# netx90_app register map
File version: 1.0
CPU: CM4 r0p1, little endian, MPU, FPU, 4 interrupt priority bits, 78 interrupts
Registers are 32-bit, read-write, reset 0x0 unless marked. A register's access mark holds for its fields unless they carry their own. Offsets are from the block's base; [hi:lo] are bit positions; {n}, {i} and the like mark numbered series; <NAME> marks a mode.

## sqi0_app
Base 0xFF801180
Same registers: sqi1_app 0xFF8011C0
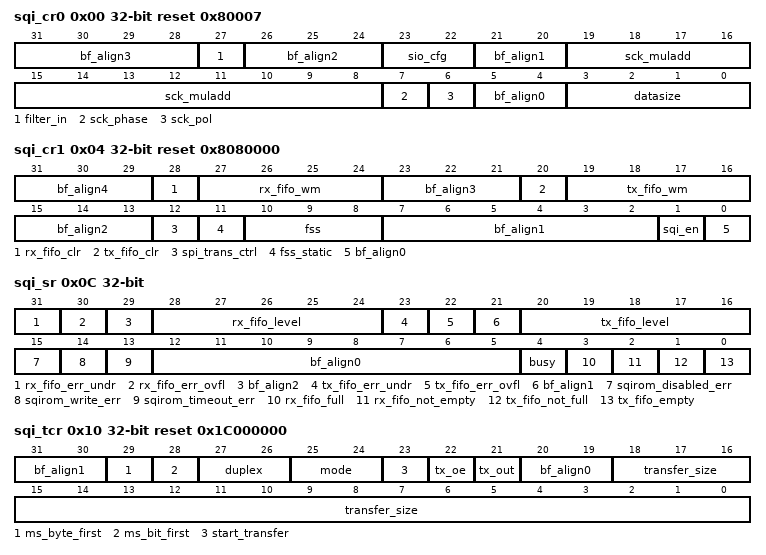
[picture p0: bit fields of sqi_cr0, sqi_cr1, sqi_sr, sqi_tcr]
0x00 sqi_cr0 reset 0x80007 (reset mask 0x8CFFFCF) — SQI control register 0 This register is compatible with the netX50 and netX10 SPI module, but some additional settings are possible. The SQI module provides master function only. Slave settings are omitted. The SQI module does not support the compatible mode for netX100.
  [31:28] bf_align3 — bitField alignment value for aeabi compatibility
  [27] filter_in — Input filtering Receive data is sampled every 10 ns (100 MHz system clock). If this bit is set, the stored receive value will be the result of a majority decision of the three sampling points around an sck clock edge (if two or more '1's have been sampled, a '1' will be stored. If this bit is not set, a '0' will be stored). Input filtering should be used for sck_muladd<=0x200 (i.e. below 12.5 MHz). For higher frequencies, stable signal phases are too short for filtering.
  [26:24] bf_align2 — bitField alignment value for aeabi compatibility
  [23:22] sio_cfg — SQI IO configuration Default: All additional SQI-IOs (SIO2+3) are in PIO input mode. Coding 00: only SIO2+3 are controllable as PIOs (2-bit SPI or standard Motorola SPI) 01: all SQI IOs are used for transfers (4-bit SPI/SQI) 10: reserved 11: all SQI IOs are controllable as PIOs
  [21:20] bf_align1 — bitField alignment value for aeabi compatibility
  [19:8] sck_muladd — Serial clock rate multiply add value for sck generation sck-frequency: f_sck = (sck_muladd * 100)/4096 [MHz]. Programmed value of sck_muladd must be <= 0x800. Default value 0x800 equals 50 MHz clock rate. Note: If sck_muladd is set to zero, transfer will freeze. Note: SQIROM (XiP) serial clock rate must be programmed in register 'sqi_sqirom_cfg'.
  [7] sck_phase — Serial clock phase 1: Sample data at second clock edge, data is generated half a clock phase before sampling 0: Sample data at first clock edge, data is generated half a clock phase before sampling Note: sck_phase value equals bit 0 of SPI mode value (mode = (sck_pol, sck_phase)).
  [6] sck_pol — Serial clock polarity 0: idle: clock is low, first edge is rising 1: idle: clock is high, first edge is falling Note: sck_pol value equals bit 1 of SPI mode value (mode = (sck_pol, sck_phase)).
  [5:4] bf_align0 — bitField alignment value for aeabi compatibility
  [3:0] datasize — Data size select for standard Motorola SPI mode This bit field is unused in 2-bit and 4-bit SPI modes (i.e. data size fixed to 8 bit). The actual transfer size is 'datasize' + 1 bit. { | 0000...0010: reserved 0011: 4 bit 0100: 5 bit ... 0111: 8 bit ... 1111: 16 bit }
0x04 sqi_cr1 reset 0x8080000 (reset mask 0x1F1F1F02) — SQI control register 1 This register is compatible with the netX50 and netX10 SPI module, but some additional settings are possible. The SQI module provides master function only. Slave settings are omitted.
  [31:29] bf_align4 — bitField alignment value for aeabi compatibility
  [28] rx_fifo_clr — Receive FIFO clear Writing '1' to this bit will clear the receive FIFO. The hardware will automatically reset this bit. This bit is always '0' when read.
  [27:24] rx_fifo_wm — Receive FIFO watermark for IRQ generation If the receive FIFO watermark IRQ is enabled (bit 'RXIM' is set in register 'sqi_irq_mask'), transfers will stop when the receive FIFO runs full. Transfers will continue after the receive data is read from the receive FIFO to avoid an overflow of the receive FIFO. If the receive FIFO watermark IRQ is disabled (bit 'RXIM' is not set in register 'sqi_irq_mask'), transfers will not stop when the receive FIFO runs full. This may cause an overflow of the receive FIFO. This is compatible with netX50 behavior and allows writing data in full-duplex mode without reading the receive FIFO.
  [23:21] bf_align3 — bitField alignment value for aeabi compatibility
  [20] tx_fifo_clr — Transmit FIFO clear Writing '1' to this bit will clear the transmit FIFO. The hardware will automatically reset this bit. This bit is always '0' when read.
  [19:16] tx_fifo_wm — Transmit FIFO watermark for IRQ generation
  [15:13] bf_align2 — bitField alignment value for aeabi compatibility
  [12] spi_trans_ctrl — Transfer control for standard Motorola SPI (default: disabled) This bit is used only for standard Motorola SPI (bits 'mode' of register 'sqi_tcr') in full-duplex and half-duplex mode. If this bit is set, SPI transfers will be controlled by 'start_transfer' and 'transfer_size' of register 'sqi_tcr'. If this bit is not set (default), SPI transfers start immediately after transfer data has been written to TX FIFO (this is compatible with the SPI module). Settings of 'start_transfer' and 'transfer_size' of register 'sqi_tcr' then remain unaffected and will be ignored. If this bit is set and SPI is used in receive mode (full-duplex or half-duplex receive mode set by bit field 'duplex' in register 'sqi_tcr'), transfers will stop when the receive FIFO runs full. Transfers will continue after the receive data is read from the receive FIFO to avoid an overflow of the receive FIFO.
  [11] fss_static — SQI static chip select 0: Chip select will be generated automatically at data frame begin/end according to fss and datasize. 1: Chip select will be set statically according to 'fss' bits (see below). If fss is set to static mode, fss must be toggled manually after each data frame in Motorola SPI mode when sck_phase is 0 for compatibility with the specification! Note: This bit is used only in standard Motorola SPI mode. For SQI modes, chip select is never generated automatically.
  [10:8] fss — Frame slave select Up to 3 devices can be assigned directly. Up to 8 devices can be assigned if an external de-multiplexer is used. This signal is active low, i.e. the bits will be inverted before they are output to the SQI pins.
  [7:2] bf_align1 — bitField alignment value for aeabi compatibility
  [1] sqi_en — SQI enable 0: Interface disabled 1: Interface enabled Note: If you select the SQIROM/XiP function by bit 'enable' of register 'sqi_sqirom_cfg' (see description of register 'sqi_sqirom_cfg'), the standard SQI/SPI function will not be available.
  [0] bf_align0 — bitField alignment value for aeabi compatibility
0x08 sqi_dr — SQI data register (DR) Read access: Received data word is delivered from receive FIFO. Write access: Data word to be sent is written to send FIFO. Receive and transmit FIFO both have a depth of 16 words (standard SPI mode). The SQI mode combines both FIFOs, i.e. 64 bytes are available.
  [31:0] data — Transmit data The data must be right-aligned during writing. In Standard SPI mode only bits according to sqi_cr0.datasize are transferred. In SQI mode data must be written in full DWords (i.e. the software has to collect four bytes prior to writing). Unused bytes will not be transferred and may be padded at will (number of transferred bytes depends on sqi_tcr.transfer_size). Receive data will always be right-aligned; unused bits will be '0'.
0x0C sqi_sr ro (reset mask 0xDFDFE01F) — Read-only SQI status register Shows the current status of the SQI interface.
  [31] rx_fifo_err_undr — Receive FIFO underrun error has occurred, unexpected data has been read. To clear this status flag, clear RX FIFO (register 'sqi_cr1').
  [30] rx_fifo_err_ovfl — Receive FIFO overflow error occurred, data is lost. To clear this status flag, clear RX FIFO (register 'sqi_cr1').
  [29] bf_align2 — bitField alignment value for aeabi compatibility
  [28:24] rx_fifo_level — Receive FIFO level (number of received words to be read from the FIFO).
  [23] tx_fifo_err_undr — Transmit FIFO underrun error has occurred, unexpected data has been sent. To clear this status flag, clear TX FIFO (register 'sqi_cr1').
  [22] tx_fifo_err_ovfl — Transmit FIFO overflow error occurred, data is lost. To clear this status flag, clear TX FIFO (register 'sqi_cr1').
  [21] bf_align1 — bitField alignment value for aeabi compatibility
  [20:16] tx_fifo_level — Transmit FIFO level (number of words to be transmitted are left in the FIFO).
  [15] sqirom_disabled_err — Access to the disabled SQIROM area has occurred. To enable the SQIROM function, set bit 'enable' in register 'sqi_sqirom_cfg'. This bit can be used to determine why the IRQ 'sqirom_error' has occurred. Clearing this status flag is possible only by writing a '1' here.
  [14] sqirom_write_err — Write access to the read-only SQIROM area has occurred. This bit can be used to determine why the IRQ 'sqirom_error' has occurred. Clearing this status flag is possible only by writing a '1' here.
  [13] sqirom_timeout_err — Timeout during a read of the SQIROM area has occurred. A timeout results from a fix level of the netX serial clock IO. Check IO multiplexing configuration and make sure that the serial clock output is not externally clamped. This bit can be used to determine why the IRQ 'sqirom_error' has occurred. Clearing this status flag is possible only by writing a '1' here. The SQIROM function must be disabled and enabled again to reset module-internal state machines after this bit has been set (register 'sqirom_cfg', therefore reset and set again the 'enable' bit).
  [12:5] bf_align0 — bitField alignment value for aeabi compatibility
  [4] busy — Device is busy 1 if data is currently transmitted/received or the transmit FIFO is not empty.
  [3] rx_fifo_full — Receive FIFO is full (1 if full).
  [2] rx_fifo_not_empty — Receive FIFO is not empty (0 if empty).
  [1] tx_fifo_not_full — Transmit FIFO is not full (0 if full).
  [0] tx_fifo_empty — Transmit FIFO is empty (1 if empty).
0x10 sqi_tcr reset 0x1C000000 (reset mask 0x3FE7FFFF) — SQI transfer control This register must not be changed during a transfer (bit 'busy' of register 'sqi_sr' is '1') to avoid corrupted transfers causing damage to the hardware. Module address offset 0x10 is reserved in the netX10/50 SPI module. Thus, no compatibility problems will result from using this address for extended transfer control features.
  [31:30] bf_align1 — bitField alignment value for aeabi compatibility
  [29] ms_byte_first — Most significant byte first 2- and 4-bit mode: Writing '1' to this bit will use most significant byte first in DWords (big endian). Default is little endian In standard Motorola SPI mode this bit is ignored.
  [28] ms_bit_first — Most significant bit first 2- and 4-bit mode: Writing '1' to this bit will transfer most significant bit first (default). In standard Motorola SPI mode this bit is ignored.
  [27:26] duplex — Transfer type selection Default is '11' for standard SPI compatibility. 00: dummy Generates 'transfer_size' + 1 serial clock periods. No change of RX and TX FIFOs. Data lines (standard Motorola SPI mode: SPI_MOSI) are controlled by 'tx_oe' and 'tx_out'. 01: half-duplex receive Receives 'transfer_size' + 1 words. In 2-bit and 4-bit mode, TX-FIFO will be cleared and is not available during receive. In standard SPI mode, SPI_MOSI is controlled by 'tx_oe' and 'tx_out'. You need not fill the TX-FIFO with dummy TX-data to receive RX-data. TX FIFOs are not changed and always available. 10: half-duplex transmit Transmits 'transfer_size' + 1 words. In 2-bit and 4-bit mode, RX-FIFO will be cleared and is not available during transmit. In standard SPI mode, SPI_MISO input is ignored. RX-FIFO is available and remains unchanged. 11: full-duplex Standard Motorola SPI mode only, reserved in 2-bit and 4-bit modes. The full-duplex standard Motorola SPI mode always transmits and receives data. Transmit data is taken from TX-FIFO, receive data is stored in RX-FIFO. Note: If '11' is set in 2-bit or 4-bit mode, this is treated as 'receive' (like '01' setting). Note: In case of a FIFO error (overflow, underrun) before changing to '01' or '10', the FIFO error status bits in register 'sqi_sr' will not be cleared by half-duplex modes FIFO clearing.
  [25:24] mode — SPI/SQI mode selection 00: Standard Motorola SPI mode. 01: 2-bit SPI mode 10: 4-bit SPI mode 11: reserved
  [23] start_transfer — Transfer start signal Writing a '1' starts the transfer of transfer_size bytes or dummy cycles. The hardware will automatically reset this bit. This bit is always '0' when read. This bit is writable only after a transfer sequence is finished or if it has been terminated by a FIFO clear. Note: A transfer sequence is finished completely when 'busy' of register 'sqi_sr' is not set. Note: In standard Motorola SPI mode, this function can be controlled by bit 'spi_trans_ctrl' of register 'sqi_cr1' (for SPI module compatibility).
  [22] tx_oe — Output driver enable in dummy or standard SPI receive-only mode Writing a '1' enables the output drivers of the data pins in the dummy mode.
  [21] tx_out — Output level in dummy or standard SPI receive-only mode This bit selects the output level when the output driver is enabled in the dummy mode.
  [20:19] bf_align0 — bitField alignment value for aeabi compatibility
  [18:0] transfer_size — Number of bytes within the current SQI transaction Program (number of bytes - 1) or (number of dummy clock cycles - 1). Example: { | 0x00000: one byte/dummy cycle ... 0x7ffff: 512k bytes/dummy cycles } This bit field counts down during transfers with each transferred word/byte or dummy cycle. This bit field is writable only after a transfer sequence is finished or if it has been terminated by a FIFO clear. Hence, this bit is writable, but it can also be changed by hardware. A running transfer sequence can be terminated by clearing the FIFO (register 'sqi_cr1'). This may become necessary for terminating a read sequence. Example: A half-duplex write transfer of 128 kbytes has been programmed, but there is not enough write data. To terminate this write sequence, clear the TX FIFO. If an external transfer is running while the FIFO is being cleared, this transfer will be continued and finished with the last bit to be transferred. Note: A transfer sequence is finished completely when 'busy' of register 'sqi_sr' is not set.
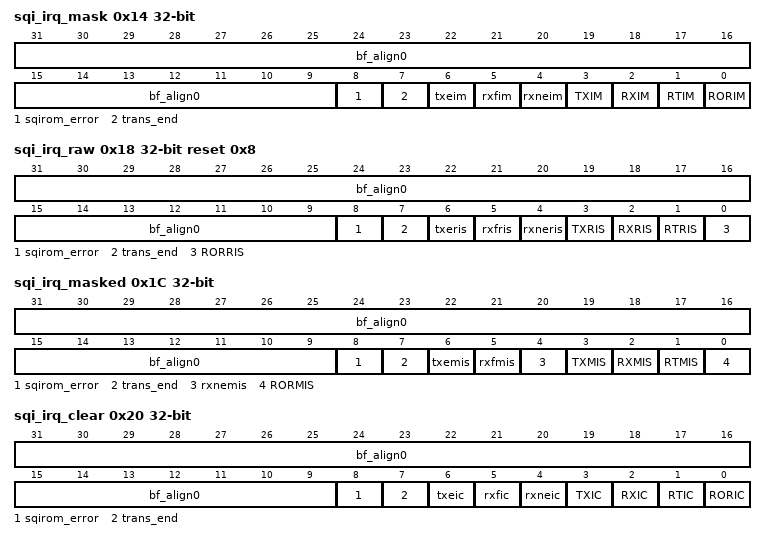
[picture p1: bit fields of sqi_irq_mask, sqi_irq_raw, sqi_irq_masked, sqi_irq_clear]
0x14 sqi_irq_mask (reset mask 0x1FF) — SQI interrupt mask register: IRQ mask is an AND-mask: Only raw interrupts with mask bit set can generate a module IRQ to CPU. For detailed IRQ behavior and function, see register 'sqi_irq_raw'. The functionality of this register is similar to that of the corresponding SPI register spi_imsc. In contrast to this register, setting bits in spi_imsc also clears the corresponding raw interrupts.
  [31:9] bf_align0 — bitField alignment value for aeabi compatibility
  [8] sqirom_error — SQIROM error interrupt mask
  [7] trans_end — Transfer end interrupt mask
  [6] txeim — Transmit FIFO empty interrupt mask (for compatibility with netx100/500)
  [5] rxfim — Receive FIFO full interrupt mask (for compatibility with netx100/500)
  [4] rxneim — Receive FIFO not empty interrupt mask (for compatibility with netx100/500)
  [3] TXIM — Transmit FIFO interrupt mask
  [2] RXIM — Receive FIFO interrupt mask
  [1] RTIM — Receive timeout interrupt mask
  [0] RORIM — Receive FIFO overrun interrupt mask
0x18 sqi_irq_raw reset 0x8 (reset mask 0x1FF) — SQI interrupt state before masking register (raw interrupt). Writing a '1' to a bit clears this interrupt. IRQ flags can also be cleared by using 'sqi_irq_clear' for SPI module compatibility.
  [31:9] bf_align0 — bitField alignment value for aeabi compatibility
  [8] sqirom_error — Unmasked SQIROM error interrupt state 1: SQIROM access error detected. This IRQ will be set if an error occurs during an SQIROM access. For detailed information on the error, see SQIROM error bits in register 'sqi_sr'. For error handling, clear this IRQ bit and the bits of register 'sqi_sr'. 0: no SQIROM error detected.
  [7] trans_end — Unmasked transfer end interrupt state (related to bit 'busy' of register 'sqi_sr') 1: transfer finished. Bit 'busy' of register 'sqi_sr' has become inactive. 0: transfer not finished. Bit 'busy' of register 'sqi_sr' is active.
  [6] txeris — Unmasked transmit FIFO empty interrupt state (for compatibility with netx100/500) 1: transmit FIFO is empty 0: transmit FIFO is not empty
  [5] rxfris — Unmasked receive FIFO full interrupt state (for compatibility with netx100/500) 1: receive FIFO is full 0: receive FIFO is not full
  [4] rxneris — Unmasked receive FIFO not empty interrupt state (for compatibility with netx100/500) 1: receive FIFO is not empty 0: receive FIFO is empty
  [3] TXRIS — Unmasked transmit FIFO interrupt state 1: transmit FIFO level is below sqi_cr1.tx_fifo_wm 0: transmit FIFO is equal or higher than sqi_cr1.tx_fifo_wm
  [2] RXRIS — Unmasked receive FIFO interrupt state 1: receive FIFO is higher than sqi_cr1.rx_fifo_wm 0: receive FIFO is equal or below sqi_cr1.rx_fifo_wm Note: Before programming this IRQ, see description of bits 'spi_trans_ctrl' and 'rx_fifo_wm' of register 'sqi_cr1' for receive FIFO behavior.
  [1] RTRIS — Unmasked receive timeout interrupt state Timeout period is 32 serial clock periods (depending on adr_sqi_cr0.sck_muladd). 1: receive FIFO is not empty and has not been read out during the timeout period 0: receive FIFO is empty or read during the last timeout period
  [0] RORRIS — Unmasked receive FIFO overrun interrupt state 1: receive FIFO overrun error occurred 0: no receive FIFO overrun error occurred
0x1C sqi_irq_masked ro (reset mask 0x1FF) — SQI masked interrupt status register For detailed IRQ behavior and function, see register 'sqi_irq_raw'.
  [31:9] bf_align0 — bitField alignment value for aeabi compatibility
  [8] sqirom_error — Masked SQIROM error interrupt state
  [7] trans_end — Masked transfer end interrupt state
  [6] txemis — Masked transmit FIFO empty interrupt state (for compatibility with netx100/500)
  [5] rxfmis — Masked receive FIFO full interrupt state (for compatibility with netx100/500)
  [4] rxnemis — Masked receive FIFO not empty interrupt state (for compatibility with netx100/500)
  [3] TXMIS — Masked transmit FIFO interrupt state
  [2] RXMIS — Masked receive FIFO interrupt state
  [1] RTMIS — Masked receive timeout interrupt state
  [0] RORMIS — Masked receive FIFO overrun interrupt state
0x20 sqi_irq_clear (reset mask 0x1FF) — SQI interrupt clear register (for compatibility with netX10/50 SPI module). This register is always '0' on read. IRQ flags can also be cleared by writing register 'sqi_irq_raw'.
  [31:9] bf_align0 — bitField alignment value for aeabi compatibility
  [8] sqirom_error — Clear SQIROM error interrupt
  [7] trans_end — Clear transfer end interrupt
  [6] txeic — Clear transmit FIFO empty interrupt (for compatibility with netx100/500)
  [5] rxfic — Clear receive FIFO full interrupt (for compatibility with netx100/500)
  [4] rxneic — Clear receive FIFO not empty interrupt (for compatibility with netx100/500)
  [3] TXIC — Clear transmit FIFO interrupt
  [2] RXIC — Clear receive FIFO interrupt
  [1] RTIC — Clear receive timeout interrupt
  [0] RORIC — Clear receive FIFO overrun interrupt
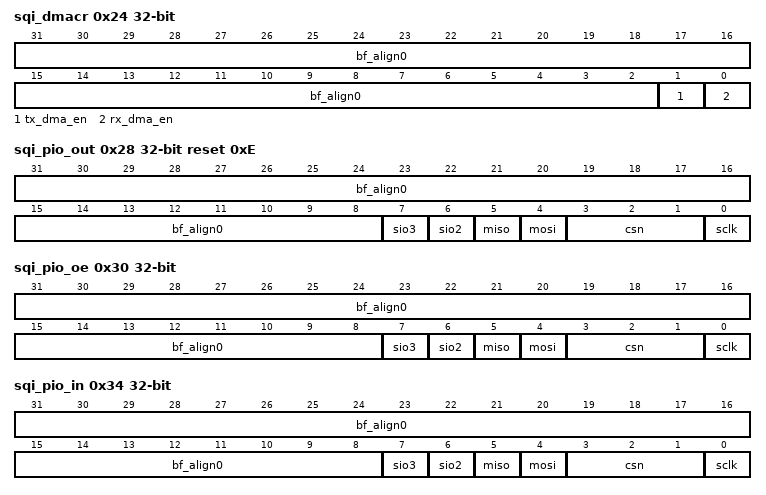
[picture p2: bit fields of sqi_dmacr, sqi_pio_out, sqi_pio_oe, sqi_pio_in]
0x24 sqi_dmacr (reset mask 0x3) — SQI DMA control register This module generates normal transfer requests only (i.e. no last requests will be issued). In consequence, you can use DMAC-controlled transfers only (no peripheral-controlled mode).
  [31:2] bf_align0 — bitField alignment value for aeabi compatibility
  [1] tx_dma_en — Enable DMA for SQI-transmit data A request will be generated if TX-FIFO is not full and sqi_cr1.sqi_en (module enable) is set. If at least 4 words are writable to the TX-FIFO, there will be a burst request to the DMAC. Set dmac_chctrl.DBSize = 1 (i.e. burst size: 4) in the DMAC module. If this bit is reset or the module is disabled, DMA request will also be reset.
  [0] rx_dma_en — Enable DMA for SQI-receive data A request will be generated if RX-FIFO is not empty and sqi_cr1.sqi_en (module enable) is set. If the RX-FIFO contains at least 4 words, there will be a burst request to the DMAC. Set dmac_chctrl.SBSize = 1 (i.e. burst size: 4) in the DMAC module. If this bit is reset or the module is disabled, DMA request will also be reset.
0x28 sqi_pio_out reset 0xE (reset mask 0xFF) — SQI PIO output level control register Bits 'sio_cfg' of register 'sqi_cr0' control the IO PIO mode. Bit 'sqi_en' of register 'sqi_cr0' has to be set to drive the SQI IOs in the PIO mode. PIO input signal states are never filtered (bit 'filter_in' of register 'sqi_cr0').
  [31:8] bf_align0 — bitField alignment value for aeabi compatibility
  [7] sio3 — SIO3 output state
  [6] sio2 — SIO2 output state
  [5] miso — MISO/SIO1 output state
  [4] mosi — MOSI/SIO0 output state
  [3:1] csn — Chip select/FSS output state {CS2, CS1, CS0}
  [0] sclk — Serial SPI clock output state
0x30 sqi_pio_oe (reset mask 0xFF) — SQI PIO output enable control register Bits 'sio_cfg' of register 'sqi_cr0' control the IO PIO mode. Bit 'sqi_en' of register 'sqi_cr0' has to be set to drive the SQI IOs in the PIO mode.
  [31:8] bf_align0 — bitField alignment value for aeabi compatibility
  [7] sio3 — SIO3 output enable
  [6] sio2 — SIO2 output enable
  [5] miso — MISO/SIO1 output enable
  [4] mosi — MOSI/SIO0 output enable
  [3:1] csn — Chip select/FSS output enable {CS2, CS1, CS0}
  [0] sclk — Serial SPI clock output enable
0x34 sqi_pio_in ro (reset mask 0xFF) — SQI PIO input status register Bits 'sio_cfg' of register 'sqi_cr0' control the IO PIO mode.
  [31:8] bf_align0 — bitField alignment value for aeabi compatibility
  [7] sio3 — SIO3 input state
  [6] sio2 — SIO2 input state
  [5] miso — MISO/SIO1 input state
  [4] mosi — MOSI/SIO0 input state
  [3:1] csn — Chip select/FSS input state {CS2, CS1, CS0}
  [0] sclk — Serial SPI clock input state
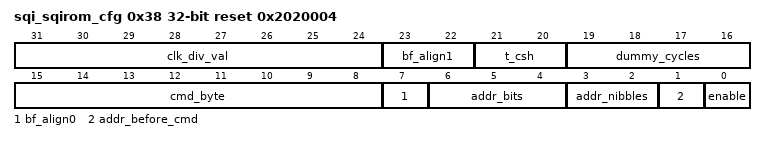
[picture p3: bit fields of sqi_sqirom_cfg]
0x38 sqi_sqirom_cfg reset 0x2020004 (reset mask 0xFF3FFF7F) — SQIROM mode configuration This mode supports the 'eXecute in Place' (XiP) feature of SQI flash chips. This register serves to configure the position of command byte and address nibbles as well as the number of address nibbles and dummy cycles. To support a wide range of frequencies for the serial clock output, you can also change the clock divider. Notes: 1. Before enabling this mode, make sure that the SQI flash chip is in 4-bit command mode, otherwise the module is not able to fetch data from the flash. 2. When enabled, the SQI module is completely blocked, i.e. other SQI or SPI transactions are not possible. 3. The chip select signal of the flash must be connected to sqi_cs0. 4. SQIROM transfers can be generated in SPI mode 0 or 3, which can be selected in register 'sqi_cr0'. DO NOT select mode 1 and 2 for SQIROM usage.
  [31:24] clk_div_val — clk400 will be divided by (clk_div_val+3) for sqirom_clk generation. Default setting '2' is 80 MHz. Maximum serial clock rate (programming '0') is 133 MHz. Serial clock period (t_sck) will be (clk_div_val+3) * 2.5 ns. Clock high and low phase will be generated symmetrically.
  [23:22] bf_align1 — bitField alignment value for aeabi compatibility
  [21:20] t_csh — Min. SQI chip select high (idle) time: (t_csh+1) * t_sck (according to clk_div_val). Programmable values are 0 to 3. Change this parameter if the SQI device used requires min. chip select high times exceeding 1 serial clock period. The data sheet of the SQI device used provides the required timing. Note: Serial clock will not toggle if the device is not selected. Hence, only chip select active timing has to be considered.
  [19:16] dummy_cycles — Selects the number of dummy cycles before data will be sampled from the SQI chip. { | 0000: 0 cycles 0001: 1 cycle 0010: 2 cycles (default) ... 1111: 15 cycles }
  [15:8] cmd_byte — This byte is transferred to the SQI chip as the command sequence. Bit 'addr_before_cmd' controls the address command order.
  [7] bf_align0 — bitField alignment value for aeabi compatibility
  [6:4] addr_bits — The number of address bits of the access address considered to generate the address for the SQI chip. This setting depends on the size of the SQI chip. { | 000: 20 bits (1-MByte/8-MBit device) (default) 001: 21 bits (2-MByte/16-MBit device) 010: 22 bits (4-MByte/32-MBit device) 011: 23 bits (8-MByte/64-MBit device) 100: 24 bits (16-MByte/128-MBit device) 101: 25 bits (32-MByte/256-MBit device) 110: 26 bits (64-MByte/512-MBit device) 111: reserved }
  [3:2] addr_nibbles — The number of nibbles to be transferred as the address to the SQI chip. This setting depends on the command format of the SQI chip. Bit 'addr_before_cmd' controls the address command order. The most significant address bits will be transmitted in the first address nibble. The least significant address bits will be transmitted in the last address nibble. 00: 5 nibbles 01: 6 nibbles (default) 10: 7 nibbles 11: 8 nibbles
  [1] addr_before_cmd — Address before command When set to '1', the address nibbles will be transferred before the command byte. Otherwise, the command will be transferred first (default).
  [0] enable — Enables the SQIROM mode of the SQI module. The SQI chip needs to be initialized to accept 4-bit read-command before you activate the SQIROM mode. This bit is also used to switch between the SQIROM/XiP and the standard SQI/SPI function. If this bit is set, the standard SQI/SPI function is not available. The SQIROM/XiP function does not depend on the programmed value of bit 'sqi_en' of register 'sqi_cr1'. If the multiplex matrix provides the SQI function, it is available only in standard SQI/SPI, but not for SQIROM/XiP usage. The SQIROM/XiP function is provided only on dedicated SQI IOs, but not as a multiplex matrix function even if standard SQI/SPI is provided there.
